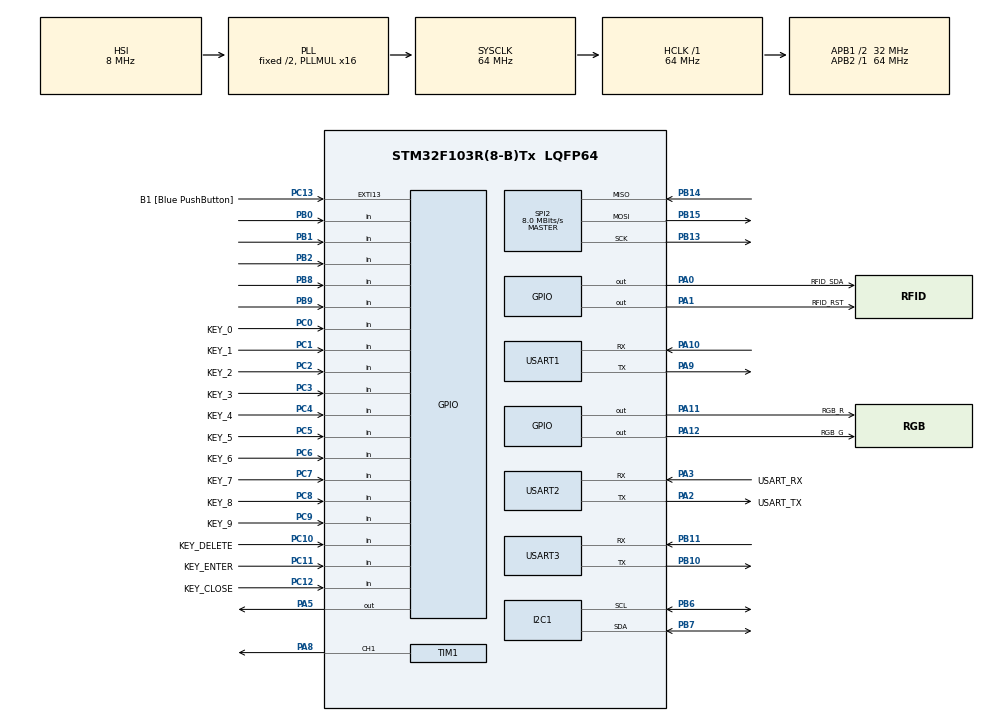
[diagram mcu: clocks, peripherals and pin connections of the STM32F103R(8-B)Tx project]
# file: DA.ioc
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Dma.Request0=USART1_TX
Dma.Request1=USART3_TX
Dma.USART1_TX.0.Direction=DMA_MEMORY_TO_PERIPH
Dma.USART1_TX.0.Instance=DMA1_Channel4
Dma.USART1_TX.0.MemDataAlignment=DMA_MDATAALIGN_BYTE
Dma.USART1_TX.0.MemInc=DMA_MINC_ENABLE
Dma.USART1_TX.0.Mode=DMA_NORMAL
Dma.USART1_TX.0.PeriphDataAlignment=DMA_PDATAALIGN_BYTE
Dma.USART1_TX.0.PeriphInc=DMA_PINC_DISABLE
Dma.USART1_TX.0.Priority=DMA_PRIORITY_LOW
Dma.USART3_TX.1.Direction=DMA_MEMORY_TO_PERIPH
Dma.USART3_TX.1.Instance=DMA1_Channel2
Dma.USART3_TX.1.MemDataAlignment=DMA_MDATAALIGN_BYTE
Dma.USART3_TX.1.MemInc=DMA_MINC_ENABLE
Dma.USART3_TX.1.Mode=DMA_NORMAL
Dma.USART3_TX.1.PeriphDataAlignment=DMA_PDATAALIGN_BYTE
Dma.USART3_TX.1.PeriphInc=DMA_PINC_DISABLE
Dma.USART3_TX.1.Priority=DMA_PRIORITY_LOW
Mcu.Family=STM32F1
Mcu.Name=STM32F103R(8-B)Tx
Mcu.Package=LQFP64
NVIC.DMA1_Channel2_IRQn=true\:0\:0\:false\:false\:true\:false\:true\:true
NVIC.DMA1_Channel4_IRQn=true\:0\:0\:false\:false\:true\:false\:true\:true
NVIC.EXTI15_10_IRQn=true\:0\:0\:false\:false\:true\:true\:true\:true
NVIC.PriorityGroup=NVIC_PRIORITYGROUP_4
NVIC.TIM2_IRQn=true\:0\:0\:false\:false\:true\:true\:true\:true
NVIC.USART1_IRQn=true\:0\:0\:false\:false\:true\:true\:true\:true
PA0-WKUP.GPIO_Label=RFID_SDA
PA0-WKUP.Signal=GPIO_Output
PA1.GPIO_Label=RFID_RST
PA1.Signal=GPIO_Output
PA10.Mode=Asynchronous
PA10.Signal=USART1_RX
PA11.GPIO_Label=RGB_R
PA11.Signal=GPIO_Output
PA12.GPIO_Label=RGB_G
PA12.Signal=GPIO_Output
PA13.GPIO_Label=TMS
PA13.Mode=Serial_Wire
PA13.Signal=SYS_JTMS-SWDIO
PA14.GPIO_Label=TCK
PA14.Mode=Serial_Wire
PA14.Signal=SYS_JTCK-SWCLK
PA2.GPIO_Label=USART_TX
PA2.GPIO_Mode=GPIO_MODE_AF_PP
PA2.GPIO_PuPd=GPIO_NOPULL
PA2.GPIO_Speed=GPIO_SPEED_FREQ_LOW
PA2.Mode=Asynchronous
PA2.Signal=USART2_TX
PA3.GPIO_Label=USART_RX
PA3.GPIO_Mode=GPIO_MODE_AF_PP
PA3.GPIO_PuPd=GPIO_NOPULL
PA3.GPIO_Speed=GPIO_SPEED_FREQ_LOW
PA3.Mode=Asynchronous
PA3.Signal=USART2_RX
PA5.Signal=GPIO_Output
PA8.Signal=S_TIM1_CH1
PA9.Mode=Asynchronous
PA9.Signal=USART1_TX
PB0.Signal=GPIO_Input
PB1.Signal=GPIO_Input
PB10.Mode=Asynchronous
PB10.Signal=USART3_TX
PB11.Mode=Asynchronous
PB11.Signal=USART3_RX
PB13.Mode=Full_Duplex_Master
PB13.Signal=SPI2_SCK
PB14.Mode=Full_Duplex_Master
PB14.Signal=SPI2_MISO
PB15.Mode=Full_Duplex_Master
PB15.Signal=SPI2_MOSI
PB2.Signal=GPIO_Input
PB6.Mode=I2C
PB6.Signal=I2C1_SCL
PB7.Mode=I2C
PB7.Signal=I2C1_SDA
PB8.Signal=GPIO_Input
PB9.Signal=GPIO_Input
PC0.GPIO_Label=KEY_0
PC0.GPIO_PuPd=GPIO_PULLUP
PC0.Signal=GPIO_Input
PC1.GPIO_Label=KEY_1
PC1.GPIO_PuPd=GPIO_PULLUP
PC1.Signal=GPIO_Input
PC10.GPIO_Label=KEY_DELETE
PC10.GPIO_PuPd=GPIO_PULLUP
PC10.Signal=GPIO_Input
PC11.GPIO_Label=KEY_ENTER
PC11.GPIO_PuPd=GPIO_PULLUP
PC11.Signal=GPIO_Input
PC12.GPIO_Label=KEY_CLOSE
PC12.GPIO_PuPd=GPIO_PULLUP
PC12.Signal=GPIO_Input
PC13-TAMPER-RTC.GPIO_Label=B1 [Blue PushButton]
PC13-TAMPER-RTC.GPIO_PuPd=GPIO_NOPULL
PC13-TAMPER-RTC.Signal=GPXTI13
PC14-OSC32_IN.Mode=LSE-External-Oscillator
PC14-OSC32_IN.Signal=RCC_OSC32_IN
PC15-OSC32_OUT.Mode=LSE-External-Oscillator
PC15-OSC32_OUT.Signal=RCC_OSC32_OUT
PC2.GPIO_Label=KEY_2
PC2.GPIO_PuPd=GPIO_PULLUP
PC2.Signal=GPIO_Input
PC3.GPIO_Label=KEY_3
PC3.GPIO_PuPd=GPIO_PULLUP
PC3.Signal=GPIO_Input
PC4.GPIO_Label=KEY_4
PC4.GPIO_PuPd=GPIO_PULLUP
PC4.Signal=GPIO_Input
PC5.GPIO_Label=KEY_5
PC5.GPIO_PuPd=GPIO_PULLUP
PC5.Signal=GPIO_Input
PC6.GPIO_Label=KEY_6
PC6.GPIO_PuPd=GPIO_PULLUP
PC6.Signal=GPIO_Input
PC7.GPIO_Label=KEY_7
PC7.GPIO_PuPd=GPIO_PULLUP
PC7.Signal=GPIO_Input
PC8.GPIO_Label=KEY_8
PC8.GPIO_PuPd=GPIO_PULLUP
PC8.Signal=GPIO_Input
PC9.GPIO_Label=KEY_9
PC9.GPIO_PuPd=GPIO_PULLUP
PC9.Signal=GPIO_Input
PD0-OSC_IN.Mode=HSE-External-Clock-Source
PD0-OSC_IN.Signal=RCC_OSC_IN
PD1-OSC_OUT.Mode=HSE-External-Clock-Source
PD1-OSC_OUT.Signal=RCC_OSC_OUT
ProjectManager.HeapSize=0x200
ProjectManager.StackSize=0x400
ProjectManager.TargetToolchain=STM32CubeIDE
RCC.AHBFreq_Value=64000000
RCC.APB1CLKDivider=RCC_HCLK_DIV2
RCC.APB1Freq_Value=32000000
RCC.APB1TimFreq_Value=64000000
RCC.APB2Freq_Value=64000000
RCC.APB2TimFreq_Value=64000000
RCC.HCLKFreq_Value=64000000
RCC.PLLMUL=RCC_PLL_MUL16
RCC.RTCClockSelection=RCC_RTCCLKSOURCE_LSE
RCC.SYSCLKFreq_VALUE=64000000
RCC.SYSCLKSource=RCC_SYSCLKSOURCE_PLLCLK
RCC.USBFreq_Value=64000000
SH.S_TIM1_CH1.0=TIM1_CH1,PWM Generation1 CH1
SPI2.BaudRatePrescaler=SPI_BAUDRATEPRESCALER_4
SPI2.CRCCalculation=SPI_CRCCALCULATION_DISABLE
SPI2.CalculateBaudRate=8.0 MBits/s
SPI2.Direction=SPI_DIRECTION_2LINES
SPI2.Mode=SPI_MODE_MASTER
SPI2.VirtualType=VM_MASTER
TIM1.Channel-PWM\ Generation1\ CH1=TIM_CHANNEL_1
TIM1.Period=999
TIM1.Prescaler=1279
TIM2.Period=9
TIM2.Prescaler=31999
USART1.VirtualMode=VM_ASYNC
USART2.VirtualMode=VM_ASYNC
USART3.VirtualMode=VM_ASYNC
VP_RTC_VS_RTC_Activate.Mode=RTC_Enabled
VP_RTC_VS_RTC_Calendar.Mode=RTC_Calendar
VP_TIM1_VS_ClockSourceINT.Mode=Internal
VP_TIM2_VS_ClockSourceINT.Mode=Internal
board=NUCLEO-F103RB

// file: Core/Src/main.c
/* USER CODE BEGIN Header */
/**
  ******************************************************************************
  * @file           : main.c
  * @brief          : Main program body
  ******************************************************************************
  * @attention
  *
  * Copyright (c) 2024 STMicroelectronics.
  * All rights reserved.
  *
  * This software is licensed under terms that can be found in the LICENSE file
  * in the root directory of this software component.
  * If no LICENSE file comes with this software, it is provided AS-IS.
  *
  ******************************************************************************
  */
/* USER CODE END Header */
#include "main.h"

/* USER CODE BEGIN Includes */
#include "global.h"
#include "door_management_system.h"
/* USER CODE END Includes */

I2C_HandleTypeDef hi2c1;

RTC_HandleTypeDef hrtc;

SPI_HandleTypeDef hspi2;

TIM_HandleTypeDef htim1;
TIM_HandleTypeDef htim2;

UART_HandleTypeDef huart1;
UART_HandleTypeDef huart2;
UART_HandleTypeDef huart3;
DMA_HandleTypeDef hdma_usart1_tx;
DMA_HandleTypeDef hdma_usart3_tx;

void SystemClock_Config(void);
static void MX_GPIO_Init(void);
static void MX_DMA_Init(void);
static void MX_USART2_UART_Init(void);
static void MX_SPI2_Init(void);
static void MX_USART1_UART_Init(void);
static void MX_USART3_UART_Init(void);
static void MX_TIM2_Init(void);
static void MX_I2C1_Init(void);
static void MX_TIM1_Init(void);
static void MX_RTC_Init(void);

int main(void)
{

  /* MCU Configuration--------------------------------------------------------*/

  /* Reset of all peripherals, Initializes the Flash interface and the Systick. */
  HAL_Init();

  /* Configure the system clock */
  SystemClock_Config();

  /* Initialize all configured peripherals */
  MX_GPIO_Init();
  MX_DMA_Init();
  MX_USART2_UART_Init();
  MX_SPI2_Init();
  MX_USART1_UART_Init();
  MX_USART3_UART_Init();
  MX_TIM2_Init();
  MX_I2C1_Init();
  MX_TIM1_Init();
  MX_RTC_Init();
  /* USER CODE BEGIN 2 */
//  ESP32_Init();
  HAL_TIM_PWM_Start(&htim1, TIM_CHANNEL_1);
  HAL_TIM_Base_Start_IT(&htim2);
  dms_init();
  /* USER CODE END 2 */

  /* Infinite loop */
  /* USER CODE BEGIN WHILE */
  while (1)
  {
	  dms_run();
    /* USER CODE END WHILE */

  }
}

void SystemClock_Config(void)
{
  RCC_OscInitTypeDef RCC_OscInitStruct = {0};
  RCC_ClkInitTypeDef RCC_ClkInitStruct = {0};
  RCC_PeriphCLKInitTypeDef PeriphClkInit = {0};

  /** Initializes the RCC Oscillators according to the specified parameters
  * in the RCC_OscInitTypeDef structure.
  */
  RCC_OscInitStruct.OscillatorType = RCC_OSCILLATORTYPE_HSI|RCC_OSCILLATORTYPE_LSE;
  RCC_OscInitStruct.LSEState = RCC_LSE_ON;
  RCC_OscInitStruct.HSIState = RCC_HSI_ON;
  RCC_OscInitStruct.HSICalibrationValue = RCC_HSICALIBRATION_DEFAULT;
  RCC_OscInitStruct.PLL.PLLState = RCC_PLL_ON;
  RCC_OscInitStruct.PLL.PLLSource = RCC_PLLSOURCE_HSI_DIV2;
  RCC_OscInitStruct.PLL.PLLMUL = RCC_PLL_MUL16;
  if (HAL_RCC_OscConfig(&RCC_OscInitStruct) != HAL_OK)
  {
    Error_Handler();
  }

  /** Initializes the CPU, AHB and APB buses clocks
  */
  RCC_ClkInitStruct.ClockType = RCC_CLOCKTYPE_HCLK|RCC_CLOCKTYPE_SYSCLK
                              |RCC_CLOCKTYPE_PCLK1|RCC_CLOCKTYPE_PCLK2;
  RCC_ClkInitStruct.SYSCLKSource = RCC_SYSCLKSOURCE_PLLCLK;
  RCC_ClkInitStruct.AHBCLKDivider = RCC_SYSCLK_DIV1;
  RCC_ClkInitStruct.APB1CLKDivider = RCC_HCLK_DIV2;
  RCC_ClkInitStruct.APB2CLKDivider = RCC_HCLK_DIV1;

  if (HAL_RCC_ClockConfig(&RCC_ClkInitStruct, FLASH_LATENCY_2) != HAL_OK)
  {
    Error_Handler();
  }
  PeriphClkInit.PeriphClockSelection = RCC_PERIPHCLK_RTC;
  PeriphClkInit.RTCClockSelection = RCC_RTCCLKSOURCE_LSE;
  if (HAL_RCCEx_PeriphCLKConfig(&PeriphClkInit) != HAL_OK)
  {
    Error_Handler();
  }
}

static void MX_I2C1_Init(void)
{

  hi2c1.Instance = I2C1;
  hi2c1.Init.ClockSpeed = 100000;
  hi2c1.Init.DutyCycle = I2C_DUTYCYCLE_2;
  hi2c1.Init.OwnAddress1 = 0;
  hi2c1.Init.AddressingMode = I2C_ADDRESSINGMODE_7BIT;
  hi2c1.Init.DualAddressMode = I2C_DUALADDRESS_DISABLE;
  hi2c1.Init.OwnAddress2 = 0;
  hi2c1.Init.GeneralCallMode = I2C_GENERALCALL_DISABLE;
  hi2c1.Init.NoStretchMode = I2C_NOSTRETCH_DISABLE;
  if (HAL_I2C_Init(&hi2c1) != HAL_OK)
  {
    Error_Handler();
  }

}

static void MX_RTC_Init(void)
{

  RTC_TimeTypeDef sTime = {0};
  RTC_DateTypeDef DateToUpdate = {0};

  /** Initialize RTC Only
  */
  hrtc.Instance = RTC;
  hrtc.Init.AsynchPrediv = RTC_AUTO_1_SECOND;
  hrtc.Init.OutPut = RTC_OUTPUTSOURCE_ALARM;
  if (HAL_RTC_Init(&hrtc) != HAL_OK)
  {
    Error_Handler();
  }

  /** Initialize RTC and set the Time and Date
  */
  sTime.Hours = 0x0;
  sTime.Minutes = 0x0;
  sTime.Seconds = 0x0;

  if (HAL_RTC_SetTime(&hrtc, &sTime, RTC_FORMAT_BCD) != HAL_OK)
  {
    Error_Handler();
  }
  DateToUpdate.WeekDay = RTC_WEEKDAY_MONDAY;
  DateToUpdate.Month = RTC_MONTH_JANUARY;
  DateToUpdate.Date = 0x1;
  DateToUpdate.Year = 0x0;

  if (HAL_RTC_SetDate(&hrtc, &DateToUpdate, RTC_FORMAT_BCD) != HAL_OK)
  {
    Error_Handler();
  }

}

static void MX_SPI2_Init(void)
{

  /* SPI2 parameter configuration*/
  hspi2.Instance = SPI2;
  hspi2.Init.Mode = SPI_MODE_MASTER;
  hspi2.Init.Direction = SPI_DIRECTION_2LINES;
  hspi2.Init.DataSize = SPI_DATASIZE_8BIT;
  hspi2.Init.CLKPolarity = SPI_POLARITY_LOW;
  hspi2.Init.CLKPhase = SPI_PHASE_1EDGE;
  hspi2.Init.NSS = SPI_NSS_SOFT;
  hspi2.Init.BaudRatePrescaler = SPI_BAUDRATEPRESCALER_4;
  hspi2.Init.FirstBit = SPI_FIRSTBIT_MSB;
  hspi2.Init.TIMode = SPI_TIMODE_DISABLE;
  hspi2.Init.CRCCalculation = SPI_CRCCALCULATION_DISABLE;
  hspi2.Init.CRCPolynomial = 10;
  if (HAL_SPI_Init(&hspi2) != HAL_OK)
  {
    Error_Handler();
  }

}

static void MX_TIM1_Init(void)
{

  TIM_ClockConfigTypeDef sClockSourceConfig = {0};
  TIM_MasterConfigTypeDef sMasterConfig = {0};
  TIM_OC_InitTypeDef sConfigOC = {0};
  TIM_BreakDeadTimeConfigTypeDef sBreakDeadTimeConfig = {0};

  htim1.Instance = TIM1;
  htim1.Init.Prescaler = 1279;
  htim1.Init.CounterMode = TIM_COUNTERMODE_UP;
  htim1.Init.Period = 999;
  htim1.Init.ClockDivision = TIM_CLOCKDIVISION_DIV1;
  htim1.Init.RepetitionCounter = 0;
  htim1.Init.AutoReloadPreload = TIM_AUTORELOAD_PRELOAD_DISABLE;
  if (HAL_TIM_Base_Init(&htim1) != HAL_OK)
  {
    Error_Handler();
  }
  sClockSourceConfig.ClockSource = TIM_CLOCKSOURCE_INTERNAL;
  if (HAL_TIM_ConfigClockSource(&htim1, &sClockSourceConfig) != HAL_OK)
  {
    Error_Handler();
  }
  if (HAL_TIM_PWM_Init(&htim1) != HAL_OK)
  {
    Error_Handler();
  }
  sMasterConfig.MasterOutputTrigger = TIM_TRGO_RESET;
  sMasterConfig.MasterSlaveMode = TIM_MASTERSLAVEMODE_DISABLE;
  if (HAL_TIMEx_MasterConfigSynchronization(&htim1, &sMasterConfig) != HAL_OK)
  {
    Error_Handler();
  }
  sConfigOC.OCMode = TIM_OCMODE_PWM1;
  sConfigOC.Pulse = 0;
  sConfigOC.OCPolarity = TIM_OCPOLARITY_HIGH;
  sConfigOC.OCNPolarity = TIM_OCNPOLARITY_HIGH;
  sConfigOC.OCFastMode = TIM_OCFAST_DISABLE;
  sConfigOC.OCIdleState = TIM_OCIDLESTATE_RESET;
  sConfigOC.OCNIdleState = TIM_OCNIDLESTATE_RESET;
  if (HAL_TIM_PWM_ConfigChannel(&htim1, &sConfigOC, TIM_CHANNEL_1) != HAL_OK)
  {
    Error_Handler();
  }
  sBreakDeadTimeConfig.OffStateRunMode = TIM_OSSR_DISABLE;
  sBreakDeadTimeConfig.OffStateIDLEMode = TIM_OSSI_DISABLE;
  sBreakDeadTimeConfig.LockLevel = TIM_LOCKLEVEL_OFF;
  sBreakDeadTimeConfig.DeadTime = 0;
  sBreakDeadTimeConfig.BreakState = TIM_BREAK_DISABLE;
  sBreakDeadTimeConfig.BreakPolarity = TIM_BREAKPOLARITY_HIGH;
  sBreakDeadTimeConfig.AutomaticOutput = TIM_AUTOMATICOUTPUT_DISABLE;
  if (HAL_TIMEx_ConfigBreakDeadTime(&htim1, &sBreakDeadTimeConfig) != HAL_OK)
  {
    Error_Handler();
  }
  HAL_TIM_MspPostInit(&htim1);

}

static void MX_TIM2_Init(void)
{

  TIM_ClockConfigTypeDef sClockSourceConfig = {0};
  TIM_MasterConfigTypeDef sMasterConfig = {0};

  htim2.Instance = TIM2;
  htim2.Init.Prescaler = 31999;
  htim2.Init.CounterMode = TIM_COUNTERMODE_UP;
  htim2.Init.Period = 9;
  htim2.Init.ClockDivision = TIM_CLOCKDIVISION_DIV1;
  htim2.Init.AutoReloadPreload = TIM_AUTORELOAD_PRELOAD_DISABLE;
  if (HAL_TIM_Base_Init(&htim2) != HAL_OK)
  {
    Error_Handler();
  }
  sClockSourceConfig.ClockSource = TIM_CLOCKSOURCE_INTERNAL;
  if (HAL_TIM_ConfigClockSource(&htim2, &sClockSourceConfig) != HAL_OK)
  {
    Error_Handler();
  }
  sMasterConfig.MasterOutputTrigger = TIM_TRGO_RESET;
  sMasterConfig.MasterSlaveMode = TIM_MASTERSLAVEMODE_DISABLE;
  if (HAL_TIMEx_MasterConfigSynchronization(&htim2, &sMasterConfig) != HAL_OK)
  {
    Error_Handler();
  }

}

static void MX_USART1_UART_Init(void)
{

  huart1.Instance = USART1;
  huart1.Init.BaudRate = 115200;
  huart1.Init.WordLength = UART_WORDLENGTH_8B;
  huart1.Init.StopBits = UART_STOPBITS_1;
  huart1.Init.Parity = UART_PARITY_NONE;
  huart1.Init.Mode = UART_MODE_TX_RX;
  huart1.Init.HwFlowCtl = UART_HWCONTROL_NONE;
  huart1.Init.OverSampling = UART_OVERSAMPLING_16;
  if (HAL_UART_Init(&huart1) != HAL_OK)
  {
    Error_Handler();
  }

}

static void MX_USART2_UART_Init(void)
{

  huart2.Instance = USART2;
  huart2.Init.BaudRate = 115200;
  huart2.Init.WordLength = UART_WORDLENGTH_8B;
  huart2.Init.StopBits = UART_STOPBITS_1;
  huart2.Init.Parity = UART_PARITY_NONE;
  huart2.Init.Mode = UART_MODE_TX_RX;
  huart2.Init.HwFlowCtl = UART_HWCONTROL_NONE;
  huart2.Init.OverSampling = UART_OVERSAMPLING_16;
  if (HAL_UART_Init(&huart2) != HAL_OK)
  {
    Error_Handler();
  }

}

static void MX_USART3_UART_Init(void)
{

  huart3.Instance = USART3;
  huart3.Init.BaudRate = 115200;
  huart3.Init.WordLength = UART_WORDLENGTH_8B;
  huart3.Init.StopBits = UART_STOPBITS_1;
  huart3.Init.Parity = UART_PARITY_NONE;
  huart3.Init.Mode = UART_MODE_TX_RX;
  huart3.Init.HwFlowCtl = UART_HWCONTROL_NONE;
  huart3.Init.OverSampling = UART_OVERSAMPLING_16;
  if (HAL_UART_Init(&huart3) != HAL_OK)
  {
    Error_Handler();
  }

}

static void MX_DMA_Init(void)
{

  /* DMA controller clock enable */
  __HAL_RCC_DMA1_CLK_ENABLE();

  /* DMA interrupt init */
  /* DMA1_Channel2_IRQn interrupt configuration */
  HAL_NVIC_SetPriority(DMA1_Channel2_IRQn, 0, 0);
  HAL_NVIC_EnableIRQ(DMA1_Channel2_IRQn);
  /* DMA1_Channel4_IRQn interrupt configuration */
  HAL_NVIC_SetPriority(DMA1_Channel4_IRQn, 0, 0);
  HAL_NVIC_EnableIRQ(DMA1_Channel4_IRQn);

}

static void MX_GPIO_Init(void)
{
  GPIO_InitTypeDef GPIO_InitStruct = {0};

  /* GPIO Ports Clock Enable */
  __HAL_RCC_GPIOC_CLK_ENABLE();
  __HAL_RCC_GPIOD_CLK_ENABLE();
  __HAL_RCC_GPIOA_CLK_ENABLE();
  __HAL_RCC_GPIOB_CLK_ENABLE();

  /*Configure GPIO pin Output Level */
  HAL_GPIO_WritePin(GPIOA, RFID_SDA_Pin|RFID_RST_Pin|GPIO_PIN_5|RGB_R_Pin
                          |RGB_G_Pin, GPIO_PIN_RESET);

  /*Configure GPIO pin : B1_Pin */
  GPIO_InitStruct.Pin = B1_Pin;
  GPIO_InitStruct.Mode = GPIO_MODE_IT_RISING;
  GPIO_InitStruct.Pull = GPIO_NOPULL;
  HAL_GPIO_Init(B1_GPIO_Port, &GPIO_InitStruct);

  /*Configure GPIO pins : KEY_0_Pin KEY_1_Pin KEY_2_Pin KEY_3_Pin
                           KEY_4_Pin KEY_5_Pin KEY_6_Pin KEY_7_Pin
                           KEY_8_Pin KEY_9_Pin KEY_DELETE_Pin KEY_ENTER_Pin
                           KEY_CLOSE_Pin */
  GPIO_InitStruct.Pin = KEY_0_Pin|KEY_1_Pin|KEY_2_Pin|KEY_3_Pin
                          |KEY_4_Pin|KEY_5_Pin|KEY_6_Pin|KEY_7_Pin
                          |KEY_8_Pin|KEY_9_Pin|KEY_DELETE_Pin|KEY_ENTER_Pin
                          |KEY_CLOSE_Pin;
  GPIO_InitStruct.Mode = GPIO_MODE_INPUT;
  GPIO_InitStruct.Pull = GPIO_PULLUP;
  HAL_GPIO_Init(GPIOC, &GPIO_InitStruct);

  /*Configure GPIO pins : RFID_SDA_Pin RFID_RST_Pin PA5 RGB_R_Pin
                           RGB_G_Pin */
  GPIO_InitStruct.Pin = RFID_SDA_Pin|RFID_RST_Pin|GPIO_PIN_5|RGB_R_Pin
                          |RGB_G_Pin;
  GPIO_InitStruct.Mode = GPIO_MODE_OUTPUT_PP;
  GPIO_InitStruct.Pull = GPIO_NOPULL;
  GPIO_InitStruct.Speed = GPIO_SPEED_FREQ_LOW;
  HAL_GPIO_Init(GPIOA, &GPIO_InitStruct);

  /*Configure GPIO pins : PB0 PB1 PB2 PB8
                           PB9 */
  GPIO_InitStruct.Pin = GPIO_PIN_0|GPIO_PIN_1|GPIO_PIN_2|GPIO_PIN_8
                          |GPIO_PIN_9;
  GPIO_InitStruct.Mode = GPIO_MODE_INPUT;
  GPIO_InitStruct.Pull = GPIO_NOPULL;
  HAL_GPIO_Init(GPIOB, &GPIO_InitStruct);

  /* EXTI interrupt init*/
  HAL_NVIC_SetPriority(EXTI15_10_IRQn, 0, 0);
  HAL_NVIC_EnableIRQ(EXTI15_10_IRQn);

}

/* USER CODE BEGIN 4 */
void HAL_TIM_PeriodElapsedCallback(TIM_HandleTypeDef *htim){
	if(htim->Instance == TIM2){
		timer_run();
		keypad_button_reading();
	}
}
/* USER CODE END 4 */

void Error_Handler(void)
{
  __disable_irq();
  while (1)
  {
  }
}
